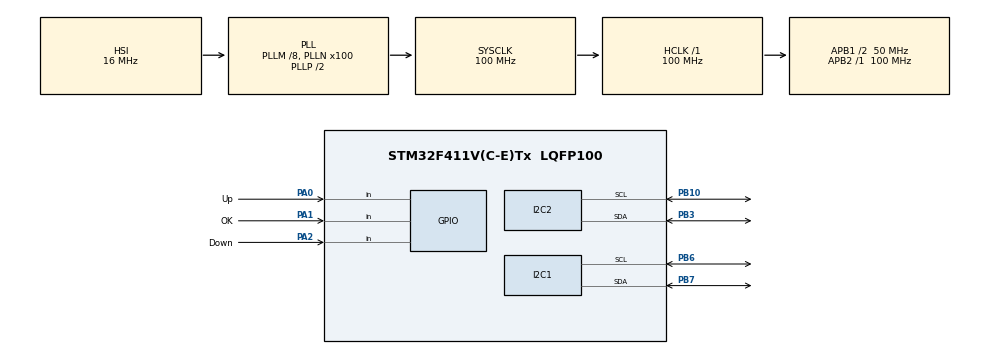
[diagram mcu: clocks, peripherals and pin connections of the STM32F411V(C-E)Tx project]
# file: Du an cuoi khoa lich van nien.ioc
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Mcu.Family=STM32F4
Mcu.Name=STM32F411V(C-E)Tx
Mcu.Package=LQFP100
NVIC.PriorityGroup=NVIC_PRIORITYGROUP_4
PA0-WKUP.GPIO_Label=Up
PA0-WKUP.GPIO_PuPd=GPIO_PULLUP
PA0-WKUP.Signal=GPIO_Input
PA1.GPIO_Label=OK
PA1.GPIO_PuPd=GPIO_PULLUP
PA1.Signal=GPIO_Input
PA13.Mode=Serial_Wire
PA13.Signal=SYS_JTMS-SWDIO
PA14.Mode=Serial_Wire
PA14.Signal=SYS_JTCK-SWCLK
PA2.GPIO_Label=Down
PA2.GPIO_PuPd=GPIO_PULLUP
PA2.Signal=GPIO_Input
PB10.Mode=I2C
PB10.Signal=I2C2_SCL
PB3.Mode=I2C
PB3.Signal=I2C2_SDA
PB6.Mode=I2C
PB6.Signal=I2C1_SCL
PB7.Mode=I2C
PB7.Signal=I2C1_SDA
PH0\ -\ OSC_IN.Mode=HSE-External-Oscillator
PH0\ -\ OSC_IN.Signal=RCC_OSC_IN
PH1\ -\ OSC_OUT.Mode=HSE-External-Oscillator
PH1\ -\ OSC_OUT.Signal=RCC_OSC_OUT
ProjectManager.HeapSize=0x200
ProjectManager.StackSize=0x400
ProjectManager.TargetToolchain=MDK-ARM V5.32
RCC.48MHZClocksFreq_Value=50000000
RCC.AHBFreq_Value=100000000
RCC.APB1CLKDivider=RCC_HCLK_DIV2
RCC.APB1Freq_Value=50000000
RCC.APB1TimFreq_Value=100000000
RCC.APB2Freq_Value=100000000
RCC.APB2TimFreq_Value=100000000
RCC.CortexFreq_Value=100000000
RCC.HCLKFreq_Value=100000000
RCC.HSE_VALUE=25000000
RCC.HSI_VALUE=16000000
RCC.LSE_VALUE=32768
RCC.PLLM=8
RCC.PLLN=100
RCC.SYSCLKFreq_VALUE=100000000
RCC.SYSCLKSource=RCC_SYSCLKSOURCE_PLLCLK
RCC.VCOOutputFreq_Value=200000000
board=custom

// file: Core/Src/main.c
/* USER CODE BEGIN Header */
/**
  ******************************************************************************
  * @file           : main.c
  * @brief          : Main program body
  ******************************************************************************
  * @attention
  *
  * Copyright (c) 2022 STMicroelectronics.
  * All rights reserved.
  *
  * This software is licensed under terms that can be found in the LICENSE file
  * in the root directory of this software component.
  * If no LICENSE file comes with this software, it is provided AS-IS.
  *
  ******************************************************************************
  */
/* USER CODE END Header */
#include "main.h"

/* USER CODE BEGIN Includes */
#include "LiquidCrystal_I2C.h"
#include "DS3231.h"
#include "Button.h"
#include "stdio.h"
#include "Clock_Handle.h"
#include "Utils.h"
#include "Button_callback.h"

extern void button_callback_init(void);
extern void button_callback_handle(void);

/* USER CODE END Includes */

I2C_HandleTypeDef hi2c1;
I2C_HandleTypeDef hi2c2;

void SystemClock_Config(void);
static void MX_GPIO_Init(void);
static void MX_I2C1_Init(void);
static void MX_I2C2_Init(void);

int main(void)
{

  /* MCU Configuration--------------------------------------------------------*/

  /* Reset of all peripherals, Initializes the Flash interface and the Systick. */
  HAL_Init();

  /* Configure the system clock */
  SystemClock_Config();

  /* Initialize all configured peripherals */
  MX_GPIO_Init();
  MX_I2C1_Init();
  MX_I2C2_Init();
  /* USER CODE BEGIN 2 */
	 clock_init(&hi2c1);
	 button_callback_init();
  /* USER CODE END 2 */

  /* Infinite loop */
  while (1)
  {

    /* USER CODE BEGIN 3 */
	 button_callback_handle();
	 clock_handle();

  }
  /* USER CODE END 3 */
}

void SystemClock_Config(void)
{
  RCC_OscInitTypeDef RCC_OscInitStruct = {0};
  RCC_ClkInitTypeDef RCC_ClkInitStruct = {0};

  /** Configure the main internal regulator output voltage
  */
  __HAL_RCC_PWR_CLK_ENABLE();
  __HAL_PWR_VOLTAGESCALING_CONFIG(PWR_REGULATOR_VOLTAGE_SCALE1);
  /** Initializes the RCC Oscillators according to the specified parameters
  * in the RCC_OscInitTypeDef structure.
  */
  RCC_OscInitStruct.OscillatorType = RCC_OSCILLATORTYPE_HSI;
  RCC_OscInitStruct.HSIState = RCC_HSI_ON;
  RCC_OscInitStruct.HSICalibrationValue = RCC_HSICALIBRATION_DEFAULT;
  RCC_OscInitStruct.PLL.PLLState = RCC_PLL_ON;
  RCC_OscInitStruct.PLL.PLLSource = RCC_PLLSOURCE_HSI;
  RCC_OscInitStruct.PLL.PLLM = 8;
  RCC_OscInitStruct.PLL.PLLN = 100;
  RCC_OscInitStruct.PLL.PLLP = RCC_PLLP_DIV2;
  RCC_OscInitStruct.PLL.PLLQ = 4;
  if (HAL_RCC_OscConfig(&RCC_OscInitStruct) != HAL_OK)
  {
    Error_Handler();
  }
  /** Initializes the CPU, AHB and APB buses clocks
  */
  RCC_ClkInitStruct.ClockType = RCC_CLOCKTYPE_HCLK|RCC_CLOCKTYPE_SYSCLK
                              |RCC_CLOCKTYPE_PCLK1|RCC_CLOCKTYPE_PCLK2;
  RCC_ClkInitStruct.SYSCLKSource = RCC_SYSCLKSOURCE_PLLCLK;
  RCC_ClkInitStruct.AHBCLKDivider = RCC_SYSCLK_DIV1;
  RCC_ClkInitStruct.APB1CLKDivider = RCC_HCLK_DIV2;
  RCC_ClkInitStruct.APB2CLKDivider = RCC_HCLK_DIV1;

  if (HAL_RCC_ClockConfig(&RCC_ClkInitStruct, FLASH_LATENCY_3) != HAL_OK)
  {
    Error_Handler();
  }
}

static void MX_I2C1_Init(void)
{

  hi2c1.Instance = I2C1;
  hi2c1.Init.ClockSpeed = 100000;
  hi2c1.Init.DutyCycle = I2C_DUTYCYCLE_2;
  hi2c1.Init.OwnAddress1 = 0;
  hi2c1.Init.AddressingMode = I2C_ADDRESSINGMODE_7BIT;
  hi2c1.Init.DualAddressMode = I2C_DUALADDRESS_DISABLE;
  hi2c1.Init.OwnAddress2 = 0;
  hi2c1.Init.GeneralCallMode = I2C_GENERALCALL_DISABLE;
  hi2c1.Init.NoStretchMode = I2C_NOSTRETCH_DISABLE;
  if (HAL_I2C_Init(&hi2c1) != HAL_OK)
  {
    Error_Handler();
  }

}

static void MX_I2C2_Init(void)
{

  hi2c2.Instance = I2C2;
  hi2c2.Init.ClockSpeed = 100000;
  hi2c2.Init.DutyCycle = I2C_DUTYCYCLE_2;
  hi2c2.Init.OwnAddress1 = 0;
  hi2c2.Init.AddressingMode = I2C_ADDRESSINGMODE_7BIT;
  hi2c2.Init.DualAddressMode = I2C_DUALADDRESS_DISABLE;
  hi2c2.Init.OwnAddress2 = 0;
  hi2c2.Init.GeneralCallMode = I2C_GENERALCALL_DISABLE;
  hi2c2.Init.NoStretchMode = I2C_NOSTRETCH_DISABLE;
  if (HAL_I2C_Init(&hi2c2) != HAL_OK)
  {
    Error_Handler();
  }

}

static void MX_GPIO_Init(void)
{
  GPIO_InitTypeDef GPIO_InitStruct = {0};

  /* GPIO Ports Clock Enable */
  __HAL_RCC_GPIOH_CLK_ENABLE();
  __HAL_RCC_GPIOA_CLK_ENABLE();
  __HAL_RCC_GPIOB_CLK_ENABLE();

  /*Configure GPIO pins : Up_Pin OK_Pin Down_Pin */
  GPIO_InitStruct.Pin = Up_Pin|OK_Pin|Down_Pin;
  GPIO_InitStruct.Mode = GPIO_MODE_INPUT;
  GPIO_InitStruct.Pull = GPIO_PULLUP;
  HAL_GPIO_Init(GPIOA, &GPIO_InitStruct);

}

void Error_Handler(void)
{
  __disable_irq();
  while (1)
  {
  }
}
